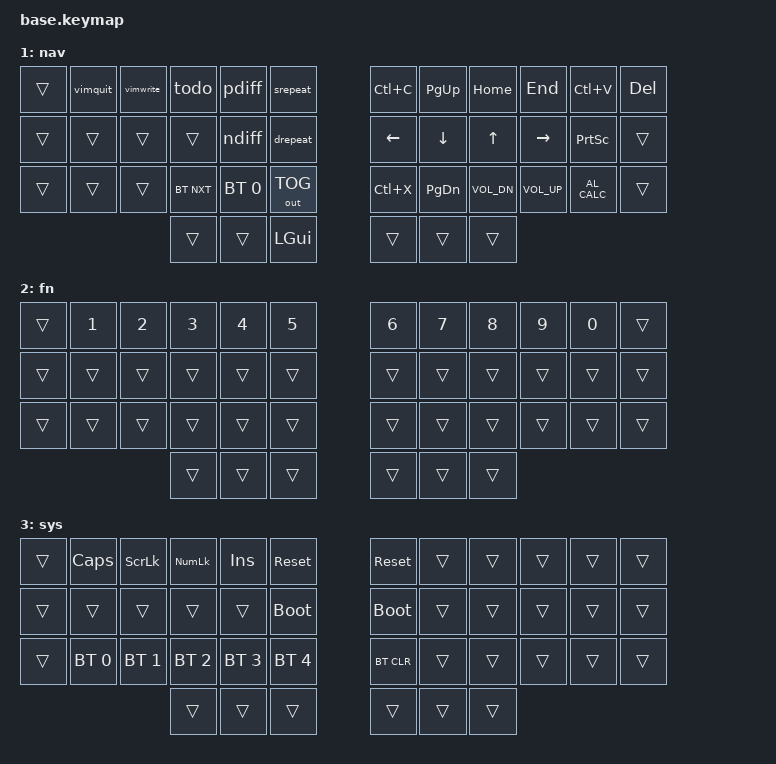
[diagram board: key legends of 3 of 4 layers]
#include <behaviors.dtsi>
#include <dt-bindings/zmk/keys.h>
#if CONFIG_WIRELESS
    #include <dt-bindings/zmk/bt.h>
    #define _BT_SEL_KEYS_ &bt BT_SEL 0 &bt BT_SEL 1 &bt BT_SEL 2 &bt BT_SEL 3 &bt BT_CLR
#else
    #define _BT_SEL_KEYS_ &trans &trans &trans &trans &trans
#endif

#include "../zmk-nodefree-config/helper.h"
#include <dt-bindings/zmk/outputs.h>

#define DEF 0
#define NAV 1
#define FN 2
#define SYS 3

#include "combos.dtsi"  // requires layer aliases
#include "mouse.dtsi"
#include "extra_keys.h"

#define XXX &none
#define ___ &trans

/* Global settings */

#define QUICK_TAP_MS 150

&sk {  // sticky-key config
    release-after-ms = <600>;  // release after 0.6s
    quick-release;             // no double capitalization when rolling keys
};

&sl {  // sticky-layer config
    ignore-modifiers;          // allow chording sticky mods & layers
};

&lt {  // layer-tap config
    flavor = "balanced";
    tapping-term-ms = <150>;
    quick-tap-ms = <QUICK_TAP_MS>;
};

&mt {
    flavor = "hold-preferred"; \
    tapping-term-ms = <220>; \
    quick-tap-ms = <220>; \
};

// macros
ZMK_BEHAVIOR(vimquit, macro,
    wait-ms = <0>;
    tap-ms = <5>;
    bindings = <&kp COLON &kp Q &kp A &kp RET>;
)

ZMK_BEHAVIOR(vimwrite, macro,
    wait-ms = <0>;
    tap-ms = <5>;
    bindings = <&kp COLON &kp W &kp A &kp EXCL &kp RET>;
)

ZMK_BEHAVIOR(srepeat, macro,
    wait-ms = <0>;
    tap-ms = <5>;
    bindings = <&kp N &kp DOT>;
)

ZMK_BEHAVIOR(drepeat, macro,
    wait-ms = <0>;
    tap-ms = <5>;
    bindings = <&kp J &kp DOT>;
)

ZMK_BEHAVIOR(ndiff, macro,
    wait-ms = <0>;
    tap-ms = <5>;
    bindings = <&kp RBKT &kp C>;
)

ZMK_BEHAVIOR(pdiff, macro,
    wait-ms = <0>;
    tap-ms = <5>;
    bindings = <&kp D &kp O>;
)

ZMK_BEHAVIOR(todo, macro,
    wait-ms = <0>;
    tap-ms = <5>;
    bindings = <&kp MINUS &kp SPACE &kp LBKT &kp SPACE &kp RBKT &kp SPACE>;
)

/* Homerow mods */

#define KEYS_L LT0 LT1 LT2 LT3 LT4 LM0 LM1 LM2 LM3 LM4 LB0 LB1 LB2 LB3 LB4  // left hand
#define KEYS_R RT0 RT1 RT2 RT3 RT4 RM0 RM1 RM2 RM3 RM4 RB0 RB1 RB2 RB3 RB4  // right hand
#define THUMBS LH2 LH1 LH0 RH0 RH1 RH2                                      // thumbs

#define MAKE_HRM(NAME, HOLD, TAP, TRIGGER_POS) \
    ZMK_BEHAVIOR(NAME, hold_tap, \
        flavor = "balanced"; \
        tapping-term-ms = <150>; \
        retro-tap; \
        bindings = <HOLD>, <TAP>; \
        hold-trigger-key-positions = <TRIGGER_POS>; \
        hold-trigger-on-release; \
    )
MAKE_HRM(hml, &kp, &kp, KEYS_R THUMBS)  // left-hand HRMs
MAKE_HRM(hmr, &kp, &kp, KEYS_L THUMBS)  // right-hand HRMs

/* Keymap */

ZMK_CONDITIONAL_LAYER(NAV FN, SYS)  // FN + NAV --> SYS

// base layer
// note fast number/symbol/fn input is through combos, take a look at combo.dtsi for detail

ZMK_LAYER(base,
//╭──────╮  ╭─────────────┬─────────────┬─────────────┬─────────────┬─────────────╮ ╭──────╮ ╭─────────────┬─────────────┬─────────────┬─────────────┬─────────────╮ ╭──────╮
&kp TAB       &kp Q         &kp W         &kp E         &kp R         &kp T                    &kp Y         &kp U         &kp I         &kp O         &kp P           &kp BSPC
//├──────┤  ├─────────────┼─────────────┼─────────────┼─────────────┼─────────────┤ ├──────┤ ├─────────────┼─────────────┼─────────────┼─────────────┼─────────────┤ ├──────┤
&kp ESC       &kp A         &kp S         &kp D         &kp F         &kp G                    &kp H         &kp J         &kp K         &kp L         &kp SEMI        &kp ENTER
//├──────┤  ├─────────────┼─────────────┼─────────────┼─────────────┼─────────────┤ ├──────┤ ├─────────────┼─────────────┼─────────────┼─────────────┼─────────────┤ ├──────┤
&kp LSHFT     &kp Z         &kp X         &kp C         &kp V         &kp B                    &kp N         &kp M         &kp COMMA     &kp DOT       &kp FSLH        &kp RSHFT
//╰──────╯  ╰─────────────┼─────────────┴─────────────┼─────────────┼─────────────┤ ├──────┤ ├─────────────┼─────────────┼─────────────┴───────────────────────────╯ ╰──────╯
                                          &kp LALT      &lt NAV SPC   &kp LCTRL                &lt FN XXX    &lt NAV SPC   &kp F11
//                                      ╰─────────────┼─────────────┴─────────────╯ ╰──────╯ ╰─────────────┴─────────────┼─────────────╯
)

// nav layer has lots of frequently used shortcuts including vim style direction/copy/cut/paste keys
// ime switch is also on this layer by using left hand thumb clusters
ZMK_LAYER(nav,
//╭──────╮  ╭─────────────┬─────────────┬─────────────┬─────────────┬─────────────╮ ╭──────╮ ╭─────────────┬─────────────┬─────────────┬─────────────┬─────────────╮ ╭──────╮
    ___       &vimquit      &vimwrite     &todo         &pdiff        &srepeat                 &kp LC(C)     &kp PG_UP     &kp HOME      &kp END        &kp LC(V)      &kp DEL
//├──────┤  ├─────────────┼─────────────┼─────────────┼─────────────┼─────────────┤ ├──────┤ ├─────────────┼─────────────┼─────────────┼─────────────┼─────────────┤ ├──────┤
    ___       ___           ___           ___           &ndiff        &drepeat                 &kp LEFT      &kp DOWN      &kp UP        &kp RIGHT      &kp PSCRN      ___
//├──────┤  ├─────────────┼─────────────┼─────────────┼─────────────┼─────────────┤ ├──────┤ ├─────────────┼─────────────┼─────────────┼─────────────┼─────────────┤ ├──────┤
    ___       ___           ___           &bt BT_NXT    &bt BT_SEL 0  &out OUT_TOG             &kp LC(X)     &kp PG_DN     &kp C_VOL_DN  &kp C_VOL_UP   &kp C_AL_CALC  ___
//╰──────╯  ╰─────────────┼─────────────┴─────────────┼─────────────┼─────────────┤ ├──────┤ ├─────────────┼─────────────┼─────────────┴───────────────────────────╯ ╰──────╯
                                          ___           ___           &kp LGUI                 ___           ___           ___
//                                      ╰─────────────┼─────────────┴─────────────╯ ╰──────╯ ╰─────────────┴─────────────┼─────────────╯
)

// fn layer are for number and mouse, they are not frequently used but would be there whenever needed
// note: number and symbol input can be done through combos, they are here when extreme steady input is needed (a.k.a passwd)
ZMK_LAYER(fn,
//╭──────╮  ╭─────────────┬─────────────┬─────────────┬─────────────┬─────────────╮ ╭──────╮ ╭─────────────┬─────────────┬─────────────┬─────────────┬─────────────╮ ╭──────╮
    ___       &kp N1        &kp N2        &kp N3        &kp N4        &kp N5                   &kp N6        &kp N7        &kp N8         &kp N9       &kp N0          ___
//├──────┤  ├─────────────┼─────────────┼─────────────┼─────────────┼─────────────┤ ├──────┤ ├─────────────┼─────────────┼─────────────┼─────────────┼─────────────┤ ├──────┤
    ___       ___           ___           ___           ___           ___                      ___           ___           ___            ___          ___             ___
//├──────┤  ├─────────────┼─────────────┼─────────────┼─────────────┼─────────────┤ ├──────┤ ├─────────────┼─────────────┼─────────────┼─────────────┼─────────────┤ ├──────┤
    ___       ___           ___           ___           ___           ___                      ___           ___           ___            ___          ___             ___
//╰──────╯  ╰─────────────┼─────────────┴─────────────┼─────────────┼─────────────┤ ├──────┤ ├─────────────┼─────────────┼─────────────┴───────────────────────────╯ ╰──────╯
                                          ___           ___           ___                      ___           ___           ___
//                                      ╰─────────────┼─────────────┴─────────────╯ ╰──────╯ ╰─────────────┴─────────────┼─────────────╯
)

ZMK_LAYER(sys,
//╭──────╮  ╭─────────────┬─────────────┬─────────────┬─────────────┬─────────────╮ ╭──────╮ ╭─────────────┬─────────────┬─────────────┬─────────────┬─────────────╮ ╭──────╮
    ___       &kp CAPS      &kp SLCK      &kp KP_NLCK   &kp INS       &sys_reset               &sys_reset    ___           ___           ___           ___             ___
//├──────┤  ├─────────────┼─────────────┼─────────────┼─────────────┼─────────────┤ ├──────┤ ├─────────────┼─────────────┼─────────────┼─────────────┼─────────────┤ ├──────┤
    ___       ___           ___           ___           ___           &bootloader              &bootloader   ___           ___           ___           ___             ___
//├──────┤  ├─────────────┼─────────────┼─────────────┼─────────────┼─────────────┤ ├──────┤ ├─────────────┼─────────────┼─────────────┼─────────────┼─────────────┤ ├──────┤
    ___       &bt BT_SEL 0  &bt BT_SEL 1  &bt BT_SEL 2  &bt BT_SEL 3  &bt BT_SEL 4             &bt BT_CLR    ___           ___           ___           ___             ___
//╰──────╯  ╰─────────────┼─────────────┴─────────────┼─────────────┼─────────────┤ ├──────┤ ├─────────────┼─────────────┼─────────────┴───────────────────────────╯ ╰──────╯
                                          ___           ___           ___                      ___           ___           ___
//                                      ╰─────────────┼─────────────┴─────────────╯ ╰──────╯ ╰─────────────┴─────────────┼─────────────╯
)

